# H5 register map
Vendor: Allwinner; Series: H5; File version: 0.1
CPU: 0, little endian, MPU, no FPU, 0 interrupt priority bits
Registers are 32-bit, read-write, reset 0x0 unless marked. A register's access mark holds for its fields unless they carry their own. Offsets are from the block's base; [hi:lo] are bit positions; {n}, {i} and the like mark numbered series; 'fields as' and 'values as' point back to an identical list; <NAME> marks a mode.

## I2S/PCM_0
Base 0x01C22000
Same registers: I2S/PCM_1 0x01C22400, I2S/PCM_2 0x01C22800
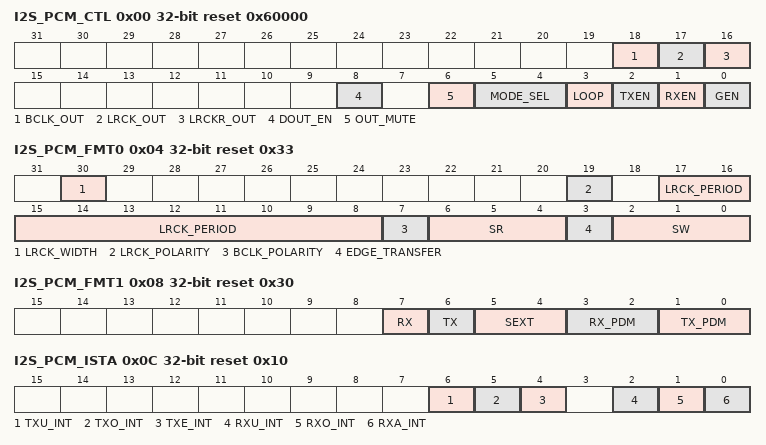
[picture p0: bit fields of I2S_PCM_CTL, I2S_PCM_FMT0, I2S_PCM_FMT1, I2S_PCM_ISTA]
0x00 I2S_PCM_CTL reset 0x60000
  [18] BCLK_OUT — 0: Input 1: Output
    0=Input; 1=Output
  [17] LRCK_OUT — 0: Input 1: Output
    0=Input; 1=Output
  [16] LRCKR_OUT — 0: Input 1: Output
    0=Input; 1=Output
  [8] DOUT_EN — 0: Disable, Hi-Z state 1: Enable
    0=Disable, Hi-Z state; 1=Enable
  [6] OUT_MUTE — 0: Normal transfer 1: Force DOUT to output 0
    0=Normal transfer; 1=Force DOUT to output 0
  [5:4] MODE_SEL — Mode Selection 00: PCM mode (offset 0: DSP_B; offset 1: DSP_A) 01: Left mode (offset 0: LJ mode; offset 1: I2S mode) 10: Right-Justified mode 11: Reserved
    0=PCM mode (offset 0: DSP_B; offset 1: DSP_A); 1=Left mode (offset 0: LJ mode; offset 1: I2S mode); 2=right_Justified_mode
  [3] LOOP — Loop Back Test 0: Normal mode 1: Loop back test Whe set , o e ti g the DOUT with the DIN
    0=Normal_mode; 1=Loop back test Whe set , o e ti g the DOUT with the DIN
  [2] TXEN — Transmitter Block Enable 0: Disable 1: Enable
    0=Disable; 1=Enable
  [1] RXEN — Receiver Block Enable 0: Disable 1: Enable
    0=Disable; 1=Enable
  [0] GEN — Globe Enable A disable on this bit overrides any other block or channel enables. 0: Disable 1: Enable
    0=Disable; 1=Enable
0x04 I2S_PCM_FMT0 reset 0x33
  [30] LRCK_WIDTH — LRCK Width(only apply in PCM mode ) 0: LRCK = 1 BCLK width (short frame) 1: LRCK = 2 BCLK width (long frame)
    0=LRCK__equals__1 (LRCK = 1 BCLK width (short frame)); 1=LRCK__equals__2 (LRCK = 2 BCLK width (long frame))
  [19] LRCK_POLARITY — When apply in I2S / Left-Justified / Right-Justified mode: 0: Left channel when LRCK is low 1: Left channel when LRCK is high When apply in PCM mode: 0: PCM LRCK asserted at the negative edge 1: PCM LRCK asserted at the positive edge
    0=low (Left channel when LRCK is low); 1=high (Left channel when LRCK is high When apply in PCM mode:); 0=PCM LRCK asserted at the negative edge; 1=PCM LRCK asserted at the positive edge
  [17:8] LRCK_PERIOD — It is used to program the number of BCLKs per channel of sample frame. This value is interpreted as follow: PCM mode: Number of BCLKs within (Left + Right) channel width I2S/Left-Justified/Right-Justified mode: Number of BCLKs within each individual channel width (Left or Right) N+1 For example: n = 7: 8 BCLK width ... n = 1023: 1024 BCLKs width
  [7] BCLK_POLARITY — 0: Normal mode, DOUT drive data at negative edge 1: Invert mode, DOUT drive data at positive edge
    0=Normal mode, DOUT drive data at negative edge; 1=Invert mode, DOUT drive data at positive edge
  [6:4] SR — Sample Resolution 000: Reserved 001: 8-bit 010: 12-bit 011: 16-bit 100: 20-bit 101: 24-bit 110: 28-bit 111: 32-bit
    1=_8_bit; 2=_12_bit; 3=_16_bit; 4=_20_bit; 5=_24_bit; 6=_28_bit; 7=_32_bit
  [3] EDGE_TRANSFER — 0: DOUT drive data and DIN sample data at the different BCLK edge 1: DOUT drive data and DIN sample data at the same BCLK edge BCLK_POLARITY = 0, EDGE_TRANSFER = 0, DIN sample data at positive edge BCLK_POLARITY = 0, EDGE_TRANSFER = 1, DIN sample data at negative edge BCLK_POLARITY = 1, EDGE_TRANSFER = 0, DIN sample data at negative edge BCLK_POLARITY = 1, EDGE_TRANSFER = 1, DIN sample data at positive edge
    0=DOUT drive data and DIN sample data at the different BCLK edge; 1=DOUT drive data and DIN sample data at the same BCLK edge BCLK_POLARITY = 0, EDGE_TRANSFER = 0, DIN sample data at positive edge BCLK_POLARITY = 0, EDGE_TRANSFER = 1, DIN sample data at negative edge BCLK_POLARITY = 1, EDGE_TRANSFER = 0, DIN sample data at negative edge BCLK_POLARITY = 1, EDGE_TRANSFER = 1, DIN sample data at positive edge
  [2:0] SW — Slot Width Select 000: Reserved 001: 8-bit 010: 12-bit 011: 16-bit 100: 20-bit 101: 24-bit 110: 28-bit 111: 32-bit
    values as SR
0x08 I2S_PCM_FMT1 reset 0x30
  [7] RX — MLS RX MSB / LSB First Select 0: MSB First 1: LSB First
    0=MSB (MSB First); 1=LSB (LSB First)
  [6] TX — MLS TX MSB / LSB First Select 0: MSB First 1: LSB First
    0=MSB (MSB First); 1=LSB (LSB First)
  [5:4] SEXT — Sign Extend in Slot [sample resolution < slot width] 00: Zeros or audio gain padding at LSB position 01: Sign extension at MSB position 10: Reserved 11: Transfer 0 after each sample in each slot
    0=Zeros or audio gain padding at LSB position; 1=Sign extension at MSB position; 3=Transfer 0 after each sample in each slot
  [3:2] RX_PDM — PCM Data Mode 00: Linear PCM 01: Reserved 10: 8-bit u-law 11: 8-bit A-law
    0=Linear_PCM; 2=_8_bit_ulaw; 3=_8_bit_Alaw
  [1:0] TX_PDM — PCM Data Mode 00: Linear PCM 01: Reserved 10: 8-bit u-law 11: 8-bit A-law
    0=Linear_PCM; 2=_8_bit_ulaw; 3=_8_bit_Alaw
0x0C I2S_PCM_ISTA reset 0x10
  [6] TXU_INT write-1-clears — TXFIFO Underrun Pending Interrupt 0: No Pending Interrupt 1: FIFO Underrun Pending Interrupt W ite to lea this i te upt.
    0=No Pending Interrupt; 1=FIFO (FIFO Underrun Pending Interrupt W ite to lea this i te upt.)
  [5] TXO_INT write-1-clears — TXFIFO Overrun Pending Interrupt 0: No Pending Interrupt 1: FIFO Overrun Pending Interrupt W ite to lea this i te upt.
    0=No Pending Interrupt; 1=FIFO (FIFO Overrun Pending Interrupt W ite to lea this i te upt.)
  [4] TXE_INT write-1-clears — TXFIFO Empty Pending Interrupt 0: No Pending IRQ 1: FIFO Empty Pending Interrupt when data in TXFIFO are less than TX trigger level W ite to lea t his interrupt or automatically clear if interrupt condition fails.
    0=No Pending IRQ; 1=FIFO (FIFO Empty Pending Interrupt when data in TXFIFO are less than TX trigger level W ite to lea t his interrupt or automatically clear if interrupt condition fails.)
  [2] RXU_INT write-1-clears — RXFIFO Underrun Pending Interrupt 0: No Pending Interrupt 1: FIFO Underrun Pending Interrupt Write 1 to clear this interrupt
    0=No Pending Interrupt; 1=FIFO (FIFO Underrun Pending Interrupt Write 1 to clear this interrupt)
  [1] RXO_INT write-1-clears — RXFIFO Overrun Pending Interrupt 0: No Pending IRQ 1: FIFO Overrun Pending IRQ W ite to lea this i te upt
    0=No Pending IRQ; 1=FIFO (FIFO Overrun Pending IRQ W ite to lea this i te upt)
  [0] RXA_INT write-1-clears — RXFIFO Data Available Pending Interrupt 0: No Pending IRQ 1: Data Available Pending IRQ when data in RXFIFO are more than RX trigger level W ite to lea this i te upt o auto ati all lea if i te upt o ditio fails.
    0=No Pending IRQ; 1=Data Available Pending IRQ when data in RXFIFO are more than RX trigger level W ite to lea this i te upt o auto ati all lea if i te upt o ditio fails
0x10 I2S_PCM_RXFIFO
  [31:0] RX_DATA ro — RX Sample Host can get one sample by reading this register. The left channel sample data is first and then the right channel sample.
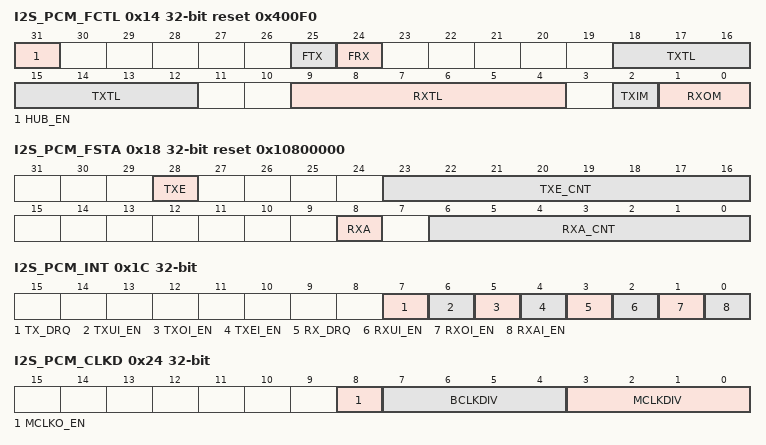
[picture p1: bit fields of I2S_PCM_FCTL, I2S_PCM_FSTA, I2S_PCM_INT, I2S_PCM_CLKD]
0x14 I2S_PCM_FCTL reset 0x400F0
  [31] HUB_EN — Audio Hub Enable 0:Disable 1:Enable
  [25] FTX — W ite to flush TXFIFO, self lea to .
  [24] FRX — W ite to flush RXFIFO, self lea to .
  [18:12] TXTL — TXFIFO Empty Trigger Level Interrupt and DMA request trigger level for TXFIFO normal condition Trigger Level = TXTL
  [9:4] RXTL — RXFIFO Trigger Level Interrupt and DMA request trigger level for RXFIFO normal condition Trigger Level = RXTL + 1
  [2] TXIM — TXFIFO Input Mode (Mode 0, 1) 0: Valid data at the MSB of TXFIFO register 1: Valid data at the LSB of TXFIFO register Example for 20-bit transmitted audio sample: Mode : TXFIFO[ : ] = {APB_WDATA[ : ], h } Mode 1:TXFIFO[31:0] = {APB_WDATA[ : ], h }
    0=Valid data at the MSB of TXFIFO register; 1=Valid data at the LSB of TXFIFO register Example for 20-bit transmitted audio sample: Mode : TXFIFO[ : ] = {APB_WDATA[ : ], h } Mode 1:TXFIFO[31:0] = {APB_WDATA[ : ], h }
  [1:0] RXOM — RXFIFO Output Mode (Mode 0, 1, 2, 3) : E pa di g at LSB of I2S/PCM_RXFIFO register. 01: Expanding received sample sign bit at MSB of I2S/PCM_RXFIFO register. 10: Truncating received samples at high half-word of I2S/PCM_RXFIFO register and low half-word of I2S/PCM_RXFIFO egiste is filled . 11: Truncating received samples at low half-word of I2S/PCM_RXFIFO register and high half-word of I2S/PCM_RXFIFO register is expanded by its sign bit. Example for 20-bit received audio sample: Mode 0: APB_RDATA[31:0] = {RXFIFO[31:12], h } Mode 1: APB_RDATA [31:0] = {12{RXFIFO[31]}, RXFIFO[31:12]} Mode : APB_RDATA [ : ] = {RXFIFO[ : ], h } Mode 3: APB_RDATA [31:0] = {16{RXFIFO[31], RXFIFO[31:16]}
    1=Expanding received sample sign bit at MSB of I2S/PCM_RXFIFO register; 2=Truncating received samples at high half-word of I2S/PCM_RXFIFO register and low half-word of I2S/PCM_RXFIFO egiste is filled ; 3=Truncating received samples at low half-word of I2S/PCM_RXFIFO register and high half-word of I2S/PCM_RXFIFO register is expanded by its sign bit. Example for 20-bit received audio sample: Mode 0: APB_RDATA[31:0] = {RXFIFO[31:12], h } Mode 1: APB_RDATA [31:0] = {12{RXFIFO[31]}, RXFIFO[31:12]} Mode : APB_RDATA [ : ] = {RXFIFO[ : ], h } Mode 3: APB_RDATA [31:0] = {16{RXFIFO[31], RXFIFO[31:16]}
0x18 I2S_PCM_FSTA reset 0x10800000
  [28] TXE ro — TXFIFO Empty 0: No room for new sample in TXFIFO 1: More than one room for new sample in TXFIFO (>= 1 word)
    0=No room for new sample in TXFIFO; 1=More than one room for new sample in TXFIFO (>= 1 word)
  [23:16] TXE_CNT ro — TXFIFO Empty Space Word Counter
  [8] RXA ro — RXFIFO Available 0: No available data in RXFIFO 1: More than one sample in RXFIFO (>= 1 word)
    0=No available data in RXFIFO; 1=More than one sample in RXFIFO (>= 1 word)
  [6:0] RXA_CNT ro — RXFIFO Available Sample Word Counter
0x1C I2S_PCM_INT
  [7] TX_DRQ — TXFIFO Empty DRQ Enable 0: Disable 1: Enable
    0=Disable; 1=Enable
  [6] TXUI_EN — TXFIFO Underrun Interrupt Enable 0: Disable 1: Enable
    0=Disable; 1=Enable
  [5] TXOI_EN — TXFIFO Overrun Interrupt Enable 0: Disable 1: Enable Whe set to , a i te upt happe s he iti g e audio data if TXFIFO is full.
    0=Disable; 1=Enable Whe set to , a i te upt happe s he iti g e audio data if TXFIFO is full
  [4] TXEI_EN — TXFIFO Empty Interrupt Enable 0: Disable 1: Enable
    0=Disable; 1=Enable
  [3] RX_DRQ — RXFIFO Data Available DRQ Enable 0: Disable 1: Enable Whe set to , RXFIFO DMA Re uest li e is asse ted if Data is a aila le i RX FIFO.
    0=Disable; 1=Enable Whe set to , RXFIFO DMA Re uest li e is asse ted if Data is a aila le i RX FIFO
  [2] RXUI_EN — RXFIFO Underrun Interrupt Enable 0: Disable 1: Enable
    0=Disable; 1=Enable
  [1] RXOI_EN — RXFIFO Overrun Interrupt Enable 0: Disable 1: Enable
    0=Disable; 1=Enable
  [0] RXAI_EN — RXFIFO Data Available Interrupt Enable 0: Disable 1: Enable
    0=Disable; 1=Enable
0x20 I2S_PCM_TXFIFO
  [31:0] TX_DATA wo — TX Sample Transmitting left, right channel sample data should be written this register one by one. The left channel sample data is first and then the right channel sample.
0x24 I2S_PCM_CLKD
  [8] MCLKO_EN — 0: Disable MCLK Output 1: Enable MCLK Output Note: Whether in slave or master mode, when this bit is set to 1, MCLK should output.
    0=Disable MCLK Output; 1=Enable MCLK Output Note: Whether in slave or master mode, when this bit is set to 1, MCLK should output
  [7:4] BCLKDIV — BCLK Divide Ratio from PLL_AUDIO 0000: Reserved 0001: Divide by 1 0010: Divide by 2 0011: Divide by 4 0100: Divide by 6 0101: Divide by 8 0110: Divide by 12 0111: Divide by 16 1000: Divide by 24 1001: Divide by 32 1010: Divide by 48 1011: Divide by 64 1100: Divide by 96 1101: Divide by 128 1110: Divide by 176 1111: Divide by 192
    1=Divide_by_1; 2=Divide_by_2; 3=Divide_by_4; 4=Divide_by_6; 5=Divide_by_8; 6=Divide_by_12; 7=Divide_by_16; 8=Divide_by_24; 9=Divide_by_32; 10=Divide_by_48; 11=Divide_by_64; 12=Divide_by_96; 13=Divide_by_128; 14=Divide_by_176; 15=Divide_by_192
  [3:0] MCLKDIV — MCLK Divide Ratio from PLL_AUDIO 0000: Reserved 0001: Divide by 1 0010: Divide by 2 0011: Divide by 4 0100: Divide by 6 0101: Divide by 8 0110: Divide by 12 0111: Divide by 16 1000: Divide by 24 1001: Divide by 32 1010: Divide by 48 1011: Divide by 64 1100: Divide by 96 1101: Divide by 128 1110: Divide by 176 1111: Divide by 192
    values as BCLKDIV
0x28 I2S_PCM_TXCNT
  [31:0] TX_CNT — TX Sample Counter The audio sample number of sending into TXFIFO. When one sample is put into TXFIFO by DMA or by host IO, the TX sample counter register increases by one. The TX sample counter register can be set to any initial value at any time. After been updated by the initial value, the counter register should count on base of this initial value.
0x2C I2S_PCM_RXCNT
  [31:0] RX_CNT — RX Sample Counter The audio sample number of writing into RXFIFO. When one sample is written by RXFIFO, the RX sample counter register increases by one. The RX sample counter register can be set to any initial value at any time. After been updated by the initial value, the counter register should count on base of this initial value.
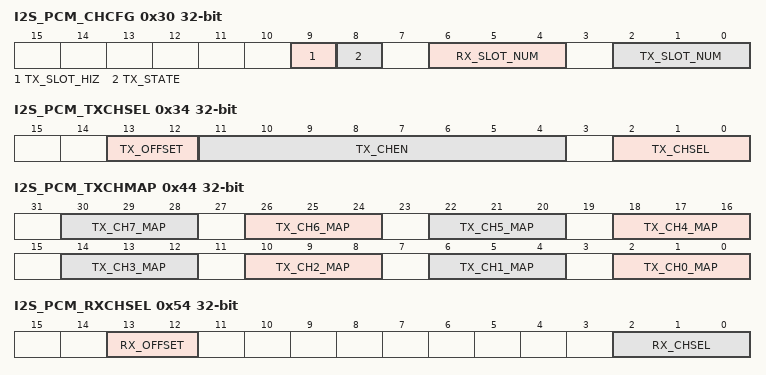
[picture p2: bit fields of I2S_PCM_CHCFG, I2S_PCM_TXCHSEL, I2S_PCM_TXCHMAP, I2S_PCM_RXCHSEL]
0x30 I2S_PCM_CHCFG
  [9] TX_SLOT_HIZ — 0: Normal mode for the last half cycle of BCLK in the slot 1: Turn to hi-z state for the last half cycle of BCLK in the slot
    0=Normal mode for the last half cycle of BCLK in the slot; 1=Turn to hi-z state for the last half cycle of BCLK in the slot
  [8] TX_STATE — 0: Transfer level 0 when not transferring slot 1: Turn to hi-z state when not transferring slot
    0=Transfer level 0 when not transferring slot; 1=Turn to hi-z state when not transferring slot
  [6:4] RX_SLOT_NUM — RX Channel/Slot Number between CPU/DMA and FIFO 000: 1 channel or slot ... 111: 8 channels or slots
    0=1 channel or slot ; 7=8 channels or slots
  [2:0] TX_SLOT_NUM — TX Channel/Slot Number between CPU/DMA and FIFO 000: 1 channel or slot ... 111: 8 channels or slots
    0=1 channel or slot ; 7=8 channels or slots
0x34 I2S_PCM_TXCHSEL
  [13:12] TX_OFFSET — TX offset tune, TX data offset to LRCK 00: No offset 01: Data is offset by 1 BCLKs to LRCK Others: Reserved
    0=No_offset; 1=Data is offset by 1 BCLKs to LRCK Others: Reserved
  [11:4] TX_CHEN — TX Channel (slot) enable, bit[11:4] refer to slot [7:0]. When one or more slot(s) is(are) disabled, the affected slot(s) is(are) set to disable state. 0: Disable 1: Enable
  [2:0] TX_CHSEL — TX Channel (slot) number select for each output 000: 1 channel / slot ... 111: 8 channels / slots
    0=1 channel / slot ; 7=8 channels / slots
0x44 I2S_PCM_TXCHMAP
  [all] fields
    0=_1st_sample; 7=_8th_sample
  [4n+2:4n] TX_CH{n}_MAP (n=0..7) — TX Channel{n} Mapping 000: 1st sample ... 111: 8th sample
0x54 I2S_PCM_RXCHSEL
  [13:12] RX_OFFSET — RX offset tune, RX data offset to LRCK 00: No offset 01: Data is offset by 1 BCLKs to LRCK Others: Reserved
    values as I2S_PCM_TXCHSEL.TX_OFFSET
  [2:0] RX_CHSEL — RX channel (slot) number select for input 000: 1 channel / slot ... 111: 8 channels / slots
    0=1 channel / slot ; 7=8 channels / slots
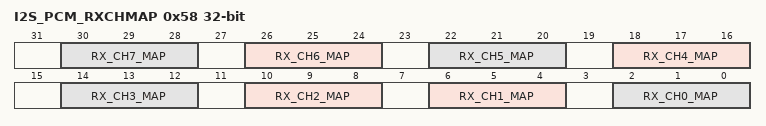
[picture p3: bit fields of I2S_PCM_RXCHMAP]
0x58 I2S_PCM_RXCHMAP
  [all] fields
    0=_1st_sample; 7=_8th_sample
  [4n+2:4n] RX_CH{n}_MAP (n=2..7) — RX Channel{n} Mapping 000: 1st sample ... 111: 8th sample
  [6:4] RX_CH1_MAP — TX Channel1 Mapping 000: 1st sample ... 111: 8th sample
  [2:0] RX_CH0_MAP — RX Channel0 Mapping 000: 1st sample ... 111: 8th sample
